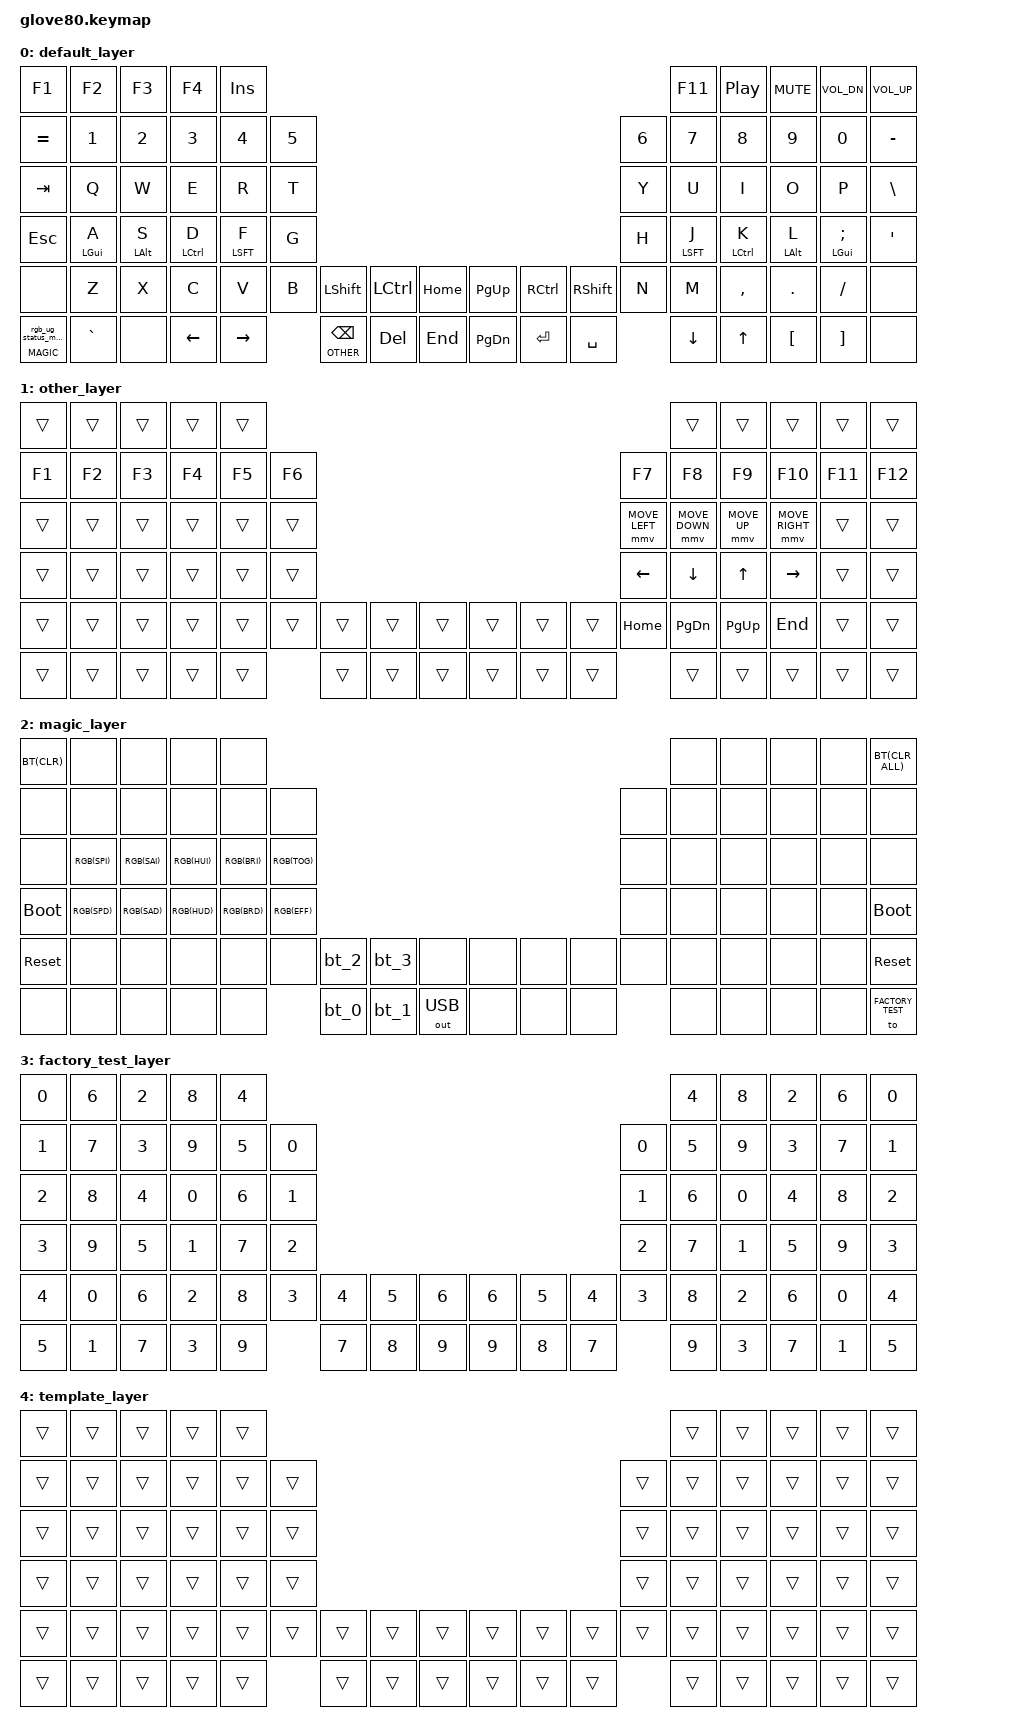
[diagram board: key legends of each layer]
// -*- mode: c; c-basic-offset: 2; indent-tabs-mode: nil -*-

/*
 * Copyright (c) 2020 The ZMK Contributors
 *
 * SPDX-License-Identifier: MIT
 */

#include <behaviors.dtsi>
#include <dt-bindings/zmk/keys.h>
#include <dt-bindings/zmk/bt.h>
#include <dt-bindings/zmk/ext_power.h>
#include <dt-bindings/zmk/outputs.h>
#include <dt-bindings/zmk/rgb.h>

#include <dt-bindings/zmk/mouse.h>

// Layers
#define DEFAULT 0
#define OTHER 1
#define MAGIC 2
#define FACTORY_TEST 3

// Glove80 key positions index for positional hold-tap
// - https://discord.com/channels/877392805654306816/937645688244826154/1066713913351221248
// - https://media.discordapp.net/attachments/937645688244826154/1066713913133121556/image.png
//
// Copied from: https://github.com/sunaku/glove80-keymaps
#define LEFT_HAND_KEYS                          \
  0  1  2  3  4                                 \
  10 11 12 13 14 15                             \
  22 23 24 25 26 27                             \
  34 35 36 37 38 39                             \
  46 47 48 49 50 51                             \
  64 65 66 67 68
#define RIGHT_HAND_KEYS                         \
  5  6  7  8  9                                 \
  16 17 18 19 20 21                             \
  28 29 30 31 32 33                             \
  40 41 42 43 44 45                             \
  58 59 60 61 62 63                             \
  75 76 77 78 79
#define THUMB_KEYS                              \
  69 52   57 74                                 \
  70 53   56 73                                 \
  71 54   55 72

/ {

  behaviors {
    //
    // Home row mod behaviours:
    // - Copied from: Copied from: https://github.com/sunaku/glove80-keymaps
    //

    //////////////////////////////////////////////////////////////////
    // Miryoku layers (thumb keys) and home row mods (non-thumb keys)
    // - https://sunaku.github.io/home-row-mods.html
    // - https://github.com/urob/zmk-config#timeless-homerow-mods
    //////////////////////////////////////////////////////////////////
    //
    // TYPING_STREAK_TERM defines how long you need to wait (milliseconds)
    // after typing before you can use home row mods again.  It prevents
    // unintended activation of home row mods when you're actively typing.
    //
    #define TYPING_STREAK_TERM 160 // global-quick-tap-ms
    //
    // KEY_REPEATING_TERM defines how much time you have left (milliseconds)
    // after tapping a key to hold it again in order to make it auto-repeat.
    //
    #define KEY_REPEATING_TERM 200 // "tap then hold" for key auto-repeat
    //
    // HOMEY_TAPPING_TERM defines how long you need to hold (milliseconds)
    // home row mod keys in order to send their modifiers to the computer
    // (i.e. "register" them) for mod-click mouse usage (e.g. Ctrl-Click).
    //
    #define HOMEY_TAPPING_TERM 260 // TAPPING_TERM + ALLOW_CROSSOVER_AFTER
    //
    // HOMEY_HOLDING_TYPE defines the flavor of ZMK hold-tap behavior to use
    // for the pinky, ring, and middle fingers (which are assigned to Super,
    // Alt, and Ctrl respectively in the Miryoku system) on home row keys.
    //
    #define HOMEY_HOLDING_TYPE "tap-preferred"
    //
    // INDEX_TAPPING_TERM defines how long you need to hold (milliseconds)
    // index finger keys in order to send their modifiers to the computer
    // (i.e. "register" them) for mod-click mouse usage (e.g. Shift-Click).
    //
    // CAUTION: You'll need to perform inward rolls from pinky->ring->middle
    // fingers toward the index fingers when activating multiple modifiers
    // because `hold-trigger-on-release` is disabled for the index fingers.
    // Otherwise, you may be surprised that the index fingers' modifier is
    // sent immediately without the rest of your multi-mod chord when you
    // perform outward rolls from your index fingers toward your pinkies.
    //
    #define INDEX_TAPPING_TERM 180
    //
    // INDEX_HOLDING_TYPE defines the flavor of ZMK hold-tap behavior to use
    // for index fingers (which Miryoku assigns to Shift) on home row keys.
    //
    // NOTE: The "tap-preferred" flavor of ZMK hold-tap for index finger keys
    // allows faster activation of the Shift modifier (without having to wait
    // for the modified key to be released as the "balanced" flavor requires).
    // Typing streaks and the `hold-trigger-on-release` setting are disabled
    // for the index fingers so as not to hinder their speed and dexterity.
    //
    #define INDEX_HOLDING_TYPE "tap-preferred"
    //
    // THUMB_TAPPING_TERM defines how long you need to hold (milliseconds)
    // a thumb key to activate a layer.  Shorter holds are treated as taps.
    //
    #define THUMB_TAPPING_TERM 160
    //
    // THUMB_HOLDING_TYPE defines the flavor of ZMK hold-tap behavior to use
    // for the thumbs (which are assigned to 6 layers in the Miryoku system).
    //
    // NOTE: The "balanced" flavor of ZMK hold-tap provides instant modifier
    // activation for the symbol layer (if the tapped symbol key is released
    // while the thumb layer key is still held down) for quicker programming.
    //
    #define THUMB_HOLDING_TYPE "balanced"

    //
    // Home row mod-tap keys for all except index fingers
    //
    homey_left: miryoku_home_row_mods_left_hand {
      compatible = "zmk,behavior-hold-tap";
      label = "HOME_ROW_MODS_LEFT_HAND";
      flavor = HOMEY_HOLDING_TYPE;
      hold-trigger-key-positions = <RIGHT_HAND_KEYS THUMB_KEYS>;
      hold-trigger-on-release; // wait for other home row mods
      tapping-term-ms = <HOMEY_TAPPING_TERM>;
      quick-tap-ms = <TYPING_STREAK_TERM>;
      global-quick-tap; // with typing streak
      #binding-cells = <2>;
      bindings = <&kp>, <&kp>;
    };
    homey_right: miryoku_home_row_mods_right_hand {
      compatible = "zmk,behavior-hold-tap";
      label = "HOME_ROW_MODS_RIGHT_HAND";
      flavor = HOMEY_HOLDING_TYPE;
      hold-trigger-key-positions = <LEFT_HAND_KEYS THUMB_KEYS>;
      hold-trigger-on-release; // wait for other home row mods
      tapping-term-ms = <HOMEY_TAPPING_TERM>;
      quick-tap-ms = <TYPING_STREAK_TERM>;
      global-quick-tap; // with typing streak
      #binding-cells = <2>;
      bindings = <&kp>, <&kp>;
    };
    //
    // Special home row mod-tap keys for the index fingers
    //
    index_left: miryoku_home_row_mods_left_index_shift {
      compatible = "zmk,behavior-hold-tap";
      label = "HOME_ROW_MODS_LEFT_INDEX_SHIFT";
      flavor = INDEX_HOLDING_TYPE;
      hold-trigger-key-positions = <RIGHT_HAND_KEYS THUMB_KEYS>;
      //hold-trigger-on-release; // don't wait for other mods
      tapping-term-ms = <INDEX_TAPPING_TERM>;
      quick-tap-ms = <KEY_REPEATING_TERM>; // enable repeat
      //global-quick-tap; // no typing streak
      #binding-cells = <2>;
      bindings = <&kp>, <&kp>;
    };
    index_right: miryoku_home_row_mods_right_index_shift {
      compatible = "zmk,behavior-hold-tap";
      label = "HOME_ROW_MODS_RIGHT_INDEX_SHIFT";
      flavor = INDEX_HOLDING_TYPE;
      hold-trigger-key-positions = <LEFT_HAND_KEYS THUMB_KEYS>;
      //hold-trigger-on-release; // don't wait for other mods
      tapping-term-ms = <INDEX_TAPPING_TERM>;
      quick-tap-ms = <KEY_REPEATING_TERM>; // enable repeat
      //global-quick-tap; // no typing streak
      #binding-cells = <2>;
      bindings = <&kp>, <&kp>;
    };

  };

  macros {
    rgb_ug_status_macro: rgb_ug_status_macro_0 {
      label = "RGB_UG_STATUS";
      compatible = "zmk,behavior-macro";
      #binding-cells = <0>;
      bindings = <&rgb_ug RGB_STATUS>;
    };

    bt_0: bt_profile_macro_0 {
      label = "BT_0";
      compatible = "zmk,behavior-macro";
      #binding-cells = <0>;
      bindings = <&out OUT_BLE>, <&bt BT_SEL 0>;
    };

    bt_1: bt_profile_macro_1 {
      label = "BT_1";
      compatible = "zmk,behavior-macro";
      #binding-cells = <0>;
      bindings = <&out OUT_BLE>, <&bt BT_SEL 1>;
    };

    bt_2: bt_profile_macro_2 {
      label = "BT_2";
      compatible = "zmk,behavior-macro";
      #binding-cells = <0>;
      bindings = <&out OUT_BLE>, <&bt BT_SEL 2>;
    };

    bt_3: bt_profile_macro_3 {
      label = "BT_3";
      compatible = "zmk,behavior-macro";
      #binding-cells = <0>;
      bindings = <&out OUT_BLE>, <&bt BT_SEL 3>;
    };
  };

  magic: magic_hold_tap {
    compatible = "zmk,behavior-hold-tap";
    label = "MAGIC_HOLD_TAP";
    #binding-cells = <2>;
    flavor = "tap-preferred";
    tapping-term-ms = <200>;
    bindings = <&mo>, <&rgb_ug_status_macro>;
  };

  keymap {
    compatible = "zmk,keymap";

// Home row mods - Left
#define _A &homey_left LGUI A
#define _S &homey_left LALT S
#define _D &homey_left LCTL D
#define _F &index_left LSFT F

// Home row mods - Right
#define _J    &index_right LSFT J
#define _K    &homey_right LCTL K
#define _L    &homey_right LALT L
#define _SEMI &homey_right LGUI SEMI
#define _QUOT &homey_right LGUI QUOT

#define _MAGIC  &magic MAGIC 0
#define _VOL_UP &kp C_VOL_UP
#define _VOL_DN &kp C_VOL_DN
#define _MUTE   &kp C_MUTE

#define OTH_BSPC &lt OTHER BSPC

// Mouse movement.
#define _MSU &mmv MOVE_UP
#define _MSD &mmv MOVE_DOWN
#define _MSL &mmv MOVE_LEFT
#define _MSR &mmv MOVE_RIGHT

// Mouse wheel movement.
#define _MWU &mwh SCROLL_UP
#define _MWD &mwh SCROLL_DOWN
#define _MWL &mwh SCROLL_LEFT
#define _MWR &mwh SCROLL_RIGHT

// Mouse buttons
#define _MBL &mkp MB1
#define _MBR &mkp MB2
#define _MBM &mkp MB3

    default_layer {
      bindings = <
        &kp F1     &kp F2    &kp F3      &kp F4      &kp INS                                               /**/                                         &kp F11  &kp C_PP    _MUTE       _VOL_DN     _VOL_UP
        &kp EQUAL  &kp N1    &kp N2      &kp N3      &kp N4      &kp N5                                    /**/                                 &kp N6  &kp N7   &kp N8      &kp N9      &kp N0      &kp MINUS
        &kp TAB    &kp Q     &kp W       &kp E       &kp R       &kp T                                     /**/                                 &kp Y   &kp U    &kp I       &kp O       &kp P       &kp BSLH
        &kp ESC    _A        _S          _D          _F          &kp G                                     /**/                                 &kp H   _J       _K          _L          _SEMI       &kp SQT
        &none      &kp Z     &kp X       &kp C       &kp V       &kp B   &kp LSHFT   &kp LCTRL   &kp HOME  /**/  &kp PG_UP &kp RCTRL &kp RSHFT  &kp N   &kp M    &kp COMMA   &kp DOT     &kp FSLH    &none
        _MAGIC     &kp GRAVE &none       &kp LEFT    &kp RIGHT           OTH_BSPC    &kp DEL     &kp END   /**/  &kp PG_DN &kp RET   &kp SPACE          &kp DOWN &kp UP      &kp LBKT    &kp RBKT    &none
        >;
    };

    other_layer {
      bindings = <
        &trans    &trans      &trans   &trans   &trans                                                     /**/                                          &trans       &trans       &trans        &trans          &trans
        &kp F1    &kp F2      &kp F3   &kp F4   &kp F5   &kp F6                                            /**/                                 &kp F7   &kp F8       &kp F9       &kp F10       &kp F11         &kp F12
        &trans    &trans      &trans   &trans   &trans   &trans                                            /**/                                 _MSL     _MSD         _MSU         _MSR          &trans          &trans
        &trans    &trans      &trans   &trans   &trans   &trans                                            /**/                                 &kp LEFT &kp DOWN     &kp UP       &kp RIGHT     &trans          &trans
        &trans    &trans      &trans   &trans   &trans   &trans   &trans    &trans    &trans               /**/   &trans    &trans    &trans    &kp HOME &kp PG_DN    &kp PG_UP    &kp END       &trans          &trans
        &trans    &trans      &trans   &trans   &trans            &trans    &trans    &trans               /**/   &trans    &trans    &trans             &trans       &trans       &trans        &trans          &trans
        >;    };

#define RGB(x) &rgb_ug RGB_ ## x
#define BT(x) &bt BT_ ## x
#define _OUT_USB &out OUT_USB
#define RESET &sys_reset
#define BOOT &bootloader

    // Keep at layer 2.
    magic_layer {
      bindings = <
        BT(CLR) &none        &none    &none    &none                                           /**/                                               &none      &none      &none      &none      BT(CLR_ALL)
        &none   &none        &none    &none    &none    &none                                  /**/                                    &none      &none      &none      &none      &none      &none
        &none   RGB(SPI)     RGB(SAI) RGB(HUI) RGB(BRI) RGB(TOG)                               /**/                                    &none      &none      &none      &none      &none      &none
        BOOT    RGB(SPD)     RGB(SAD) RGB(HUD) RGB(BRD) RGB(EFF)                               /**/                                    &none      &none      &none      &none      &none      BOOT
        RESET   &none        &none    &none    &none    &none      &bt_2     &bt_3     &none   /**/    &none     &none     &none       &none      &none      &none      &none      &none      RESET
        &none   &none        &none    &none    &none               &bt_0     &bt_1    _OUT_USB /**/    &none     &none     &none                  &none      &none      &none      &none      &to FACTORY_TEST
        >;
    };

    // Keep at layer 3.
    factory_test_layer {
      bindings = <
        &kp N0   &kp N6   &kp N2   &kp N8   &kp N4                                                                              &kp N4   &kp N8   &kp N2   &kp N6   &kp N0
        &kp N1   &kp N7   &kp N3   &kp N9   &kp N5   &kp N0                                                            &kp N0   &kp N5   &kp N9   &kp N3   &kp N7   &kp N1
        &kp N2   &kp N8   &kp N4   &kp N0   &kp N6   &kp N1                                                            &kp N1   &kp N6   &kp N0   &kp N4   &kp N8   &kp N2
        &kp N3   &kp N9   &kp N5   &kp N1   &kp N7   &kp N2                                                            &kp N2   &kp N7   &kp N1   &kp N5   &kp N9   &kp N3
        &kp N4   &kp N0   &kp N6   &kp N2   &kp N8   &kp N3   &kp N4   &kp N5   &kp N6      &kp N6   &kp N5   &kp N4   &kp N3   &kp N8   &kp N2   &kp N6   &kp N0   &kp N4
        &kp N5   &kp N1   &kp N7   &kp N3   &kp N9            &kp N7   &kp N8   &kp N9      &kp N9   &kp N8   &kp N7            &kp N9   &kp N3   &kp N7   &kp N1   &kp N5
        >;
    };

    template_layer {
      bindings = <
        &trans    &trans      &trans   &trans   &trans                                            /**/                                                  &trans       &trans       &trans        &trans          &trans
        &trans    &trans      &trans   &trans   &trans   &trans                                   /**/                                     &trans       &trans       &trans       &trans        &trans          &trans
        &trans    &trans      &trans   &trans   &trans   &trans                                   /**/                                     &trans       &trans       &trans       &trans        &trans          &trans
        &trans    &trans      &trans   &trans   &trans   &trans                                   /**/                                     &trans       &trans       &trans       &trans        &trans          &trans
        &trans    &trans      &trans   &trans   &trans   &trans   &trans      &trans      &trans  /**/   &trans      &trans      &trans    &trans       &trans       &trans       &trans        &trans          &trans
        &trans    &trans      &trans   &trans   &trans            &trans      &trans      &trans  /**/   &trans      &trans      &trans                 &trans       &trans       &trans        &trans          &trans
        >;
    };
  };
};
